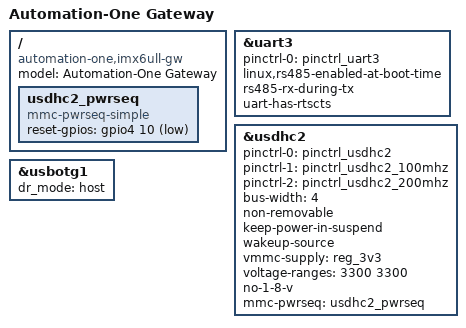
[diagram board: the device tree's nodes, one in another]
// SPDX-License-Identifier: GPL-2.0
/*
 * Copyright (C) 2017 exceet electronics GmbH
 * Copyright (C) 2019 Kontron Electronics GmbH
 */

/dts-v1/;

#include "imx6ull-kontron-n6411-som.dtsi"
#include "imx6ul-kontron-n6x1x-s.dtsi"

/ {
	model = "Automation-One Gateway";
	compatible = "automation-one,imx6ull-gw", "kontron,imx6ull-n6411-s",
		     "kontron,imx6ull-n6411-som", "fsl,imx6ull";

	/delete-node/ gpio-leds;

	usdhc2_pwrseq: usdhc2_pwrseq {
		compatible = "mmc-pwrseq-simple";
		reset-gpios = <&gpio4 10 GPIO_ACTIVE_LOW>;
	};
};

&uart3 {
      pinctrl-names = "default";
      pinctrl-0 = <&pinctrl_uart3>;
      linux,rs485-enabled-at-boot-time;
      rs485-rx-during-tx;
      uart-has-rtscts;
      status = "okay";
};

&usdhc2 {
	pinctrl-names = "default", "state_100mhz", "state_200mhz";
	pinctrl-0 = <&pinctrl_usdhc2>;
	pinctrl-1 = <&pinctrl_usdhc2_100mhz>;
	pinctrl-2 = <&pinctrl_usdhc2_200mhz>;
	bus-width = <4>;
	non-removable;
	keep-power-in-suspend;
	wakeup-source;
	vmmc-supply = <&reg_3v3>;
	voltage-ranges = <3300 3300>;
	no-1-8-v;
	mmc-pwrseq = <&usdhc2_pwrseq>;
	status = "okay";
};

&usbotg1 {
	dr_mode = "host";
};
